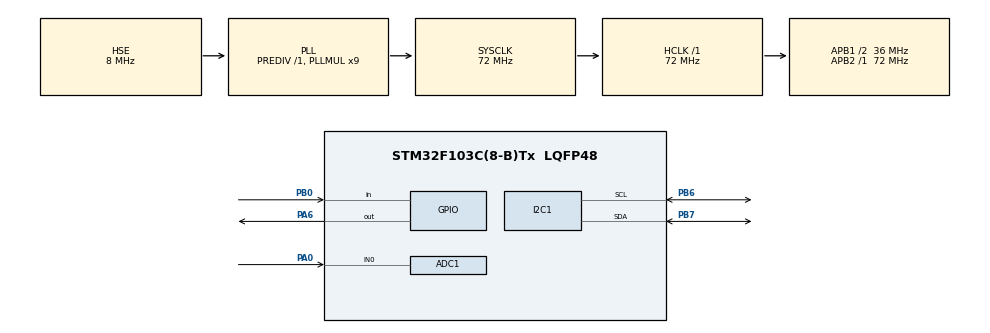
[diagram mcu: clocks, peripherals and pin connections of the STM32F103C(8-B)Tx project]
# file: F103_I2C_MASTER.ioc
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ADC1.Channel-0\#ChannelRegularConversion=ADC_CHANNEL_0
ADC1.ContinuousConvMode=ENABLE
ADC1.NbrOfConversionFlag=1
ADC1.Rank-0\#ChannelRegularConversion=1
ADC1.SamplingTime-0\#ChannelRegularConversion=ADC_SAMPLETIME_28CYCLES_5
ADC1.master=1
I2C1.AddressingMode=I2C_ADDRESSINGMODE_10BIT
I2C1.I2C_Mode=I2C_Fast
I2C1.OwnAddress=0x30F
Mcu.Family=STM32F1
Mcu.Name=STM32F103C(8-B)Tx
Mcu.Package=LQFP48
NVIC.ADC1_2_IRQn=true\:0\:0\:false\:false\:true\:true\:true
NVIC.I2C1_ER_IRQn=true\:0\:0\:false\:false\:true\:true\:true
NVIC.I2C1_EV_IRQn=true\:0\:0\:false\:false\:true\:true\:true
NVIC.PriorityGroup=NVIC_PRIORITYGROUP_4
PA0-WKUP.Signal=ADCx_IN0
PA13.Mode=Serial_Wire
PA13.Signal=SYS_JTMS-SWDIO
PA14.Mode=Serial_Wire
PA14.Signal=SYS_JTCK-SWCLK
PA6.GPIO_PuPd=GPIO_NOPULL
PA6.PinState=GPIO_PIN_SET
PA6.Signal=GPIO_Output
PB0.GPIO_PuPd=GPIO_PULLDOWN
PB0.Signal=GPIO_Input
PB6.GPIO_Mode=GPIO_MODE_AF_OD
PB6.GPIO_Speed=GPIO_SPEED_FREQ_HIGH
PB6.Mode=I2C
PB6.Signal=I2C1_SCL
PB7.GPIO_Speed=GPIO_SPEED_FREQ_HIGH
PB7.Mode=I2C
PB7.Signal=I2C1_SDA
PD0-OSC_IN.Mode=HSE-External-Oscillator
PD0-OSC_IN.Signal=RCC_OSC_IN
PD1-OSC_OUT.Mode=HSE-External-Oscillator
PD1-OSC_OUT.Signal=RCC_OSC_OUT
ProjectManager.HeapSize=0x200
ProjectManager.StackSize=0x400
ProjectManager.TargetToolchain=SW4STM32
RCC.ADCPresc=RCC_ADCPCLK2_DIV6
RCC.AHBFreq_Value=72000000
RCC.APB1CLKDivider=RCC_HCLK_DIV2
RCC.APB1Freq_Value=36000000
RCC.APB1TimFreq_Value=72000000
RCC.APB2Freq_Value=72000000
RCC.APB2TimFreq_Value=72000000
RCC.HCLKFreq_Value=72000000
RCC.PLLMUL=RCC_PLL_MUL9
RCC.PLLSourceVirtual=RCC_PLLSOURCE_HSE
RCC.SYSCLKFreq_VALUE=72000000
RCC.SYSCLKSource=RCC_SYSCLKSOURCE_PLLCLK
RCC.USBFreq_Value=72000000
SH.ADCx_IN0.0=ADC1_IN0,IN0
board=stm32f103-hal-i2c-two-boards-communication-slave

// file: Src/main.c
/* USER CODE BEGIN Header */
/**
  ******************************************************************************
  * @file           : main.c
  * @brief          : Main program body
  ******************************************************************************
  * @attention
  *
  * <h2><center>&copy; Copyright (c) 2019 STMicroelectronics.
  * All rights reserved.</center></h2>
  *
  * This software component is licensed by ST under BSD 3-Clause license,
  * the "License"; You may not use this file except in compliance with the
  * License. You may obtain a copy of the License at:
  *                        opensource.org/licenses/BSD-3-Clause
  *
  ******************************************************************************
  */
/* USER CODE END Header */

#include "main.h"

ADC_HandleTypeDef hadc1;

I2C_HandleTypeDef hi2c1;

/* USER CODE BEGIN PV */
uint8_t aTxBuffer[] = " ****I2C_TwoBoards communication based on Polling****";

/* Buffer used for reception */
uint8_t aRxBuffer[20];

/* USER CODE END PV */

void SystemClock_Config(void);
static void MX_GPIO_Init(void);
static void MX_I2C1_Init(void);
static void MX_ADC1_Init(void);
/* USER CODE BEGIN PFP */
static uint16_t Buffercmp(uint8_t* pBuffer1, uint8_t* pBuffer2, uint16_t BufferLength);
static void Error_Handler(void);
/* USER CODE END PFP */

int main(void)
{

  /* MCU Configuration--------------------------------------------------------*/

  /* Reset of all peripherals, Initializes the Flash interface and the Systick. */
  HAL_Init();

  /* Configure the system clock */
  SystemClock_Config();

  /* Initialize all configured peripherals */
  MX_GPIO_Init();
  MX_I2C1_Init();
  MX_ADC1_Init();
  /* USER CODE BEGIN 2 */
  /* The board sends the message and expects to receive it back */

    /*##-2- Start the transmission process #####################################*/
    /* While the I2C in reception process, user can transmit data through "aTxBuffer" buffer */
    /* Timeout is set to 10S */
    while(HAL_I2C_Master_Transmit(&hi2c1, (uint16_t)783, (uint8_t*)aTxBuffer, 20, 10000)!= HAL_OK)
    {
      /* Error_Handler() function is called when Timeout error occurs.
         When Acknowledge failure occurs (Slave don't acknowledge its address)
         Master restarts communication */
      if (HAL_I2C_GetError(&hi2c1) != HAL_I2C_ERROR_AF)
      {
        Error_Handler();
      }
    }

    /*##-3- Put I2C peripheral in reception process ############################*/
    /* Timeout is set to 10S */
    while(HAL_I2C_Master_Receive(&hi2c1, (uint16_t)783, (uint8_t *)aRxBuffer, 20, 10000) != HAL_OK)
    {
      /* Error_Handler() function is called when Timeout error occurs.
         When Acknowledge failure occurs (Slave don't acknowledge it's address)
         Master restarts communication */
      if (HAL_I2C_GetError(&hi2c1) != HAL_I2C_ERROR_AF)
      {
        Error_Handler();
      }
    }

    if(Buffercmp((uint8_t*)aTxBuffer,(uint8_t*)aRxBuffer,20))
    {
      /* Processing Error */
      Error_Handler();
    }
  /* USER CODE END 2 */

  /* Infinite loop */
  while (1)
  {

  }
}

static uint16_t Buffercmp(uint8_t* pBuffer1, uint8_t* pBuffer2, uint16_t BufferLength)
{
  while (BufferLength--)
  {
    if ((*pBuffer1) != *pBuffer2)
    {
      return BufferLength;
    }
    pBuffer1++;
    pBuffer2++;
  }

  return 0;
}

void SystemClock_Config(void)
{
  RCC_OscInitTypeDef RCC_OscInitStruct = {0};
  RCC_ClkInitTypeDef RCC_ClkInitStruct = {0};
  RCC_PeriphCLKInitTypeDef PeriphClkInit = {0};

  /** Initializes the CPU, AHB and APB busses clocks
  */
  RCC_OscInitStruct.OscillatorType = RCC_OSCILLATORTYPE_HSE;
  RCC_OscInitStruct.HSEState = RCC_HSE_ON;
  RCC_OscInitStruct.HSEPredivValue = RCC_HSE_PREDIV_DIV1;
  RCC_OscInitStruct.HSIState = RCC_HSI_ON;
  RCC_OscInitStruct.PLL.PLLState = RCC_PLL_ON;
  RCC_OscInitStruct.PLL.PLLSource = RCC_PLLSOURCE_HSE;
  RCC_OscInitStruct.PLL.PLLMUL = RCC_PLL_MUL9;
  if (HAL_RCC_OscConfig(&RCC_OscInitStruct) != HAL_OK)
  {
    Error_Handler();
  }
  /** Initializes the CPU, AHB and APB busses clocks
  */
  RCC_ClkInitStruct.ClockType = RCC_CLOCKTYPE_HCLK|RCC_CLOCKTYPE_SYSCLK
                              |RCC_CLOCKTYPE_PCLK1|RCC_CLOCKTYPE_PCLK2;
  RCC_ClkInitStruct.SYSCLKSource = RCC_SYSCLKSOURCE_PLLCLK;
  RCC_ClkInitStruct.AHBCLKDivider = RCC_SYSCLK_DIV1;
  RCC_ClkInitStruct.APB1CLKDivider = RCC_HCLK_DIV2;
  RCC_ClkInitStruct.APB2CLKDivider = RCC_HCLK_DIV1;

  if (HAL_RCC_ClockConfig(&RCC_ClkInitStruct, FLASH_LATENCY_2) != HAL_OK)
  {
    Error_Handler();
  }
  PeriphClkInit.PeriphClockSelection = RCC_PERIPHCLK_ADC;
  PeriphClkInit.AdcClockSelection = RCC_ADCPCLK2_DIV6;
  if (HAL_RCCEx_PeriphCLKConfig(&PeriphClkInit) != HAL_OK)
  {
    Error_Handler();
  }
}

static void MX_ADC1_Init(void)
{

  ADC_ChannelConfTypeDef sConfig = {0};

  /** Common config
  */
  hadc1.Instance = ADC1;
  hadc1.Init.ScanConvMode = ADC_SCAN_DISABLE;
  hadc1.Init.ContinuousConvMode = ENABLE;
  hadc1.Init.DiscontinuousConvMode = DISABLE;
  hadc1.Init.ExternalTrigConv = ADC_SOFTWARE_START;
  hadc1.Init.DataAlign = ADC_DATAALIGN_RIGHT;
  hadc1.Init.NbrOfConversion = 1;
  if (HAL_ADC_Init(&hadc1) != HAL_OK)
  {
    Error_Handler();
  }
  /** Configure Regular Channel
  */
  sConfig.Channel = ADC_CHANNEL_0;
  sConfig.Rank = ADC_REGULAR_RANK_1;
  sConfig.SamplingTime = ADC_SAMPLETIME_28CYCLES_5;
  if (HAL_ADC_ConfigChannel(&hadc1, &sConfig) != HAL_OK)
  {
    Error_Handler();
  }

}

static void MX_I2C1_Init(void)
{

  hi2c1.Instance = I2C1;
  hi2c1.Init.ClockSpeed = 400000;
  hi2c1.Init.DutyCycle = I2C_DUTYCYCLE_2;
  hi2c1.Init.OwnAddress1 = 783;
  hi2c1.Init.AddressingMode = I2C_ADDRESSINGMODE_10BIT;
  hi2c1.Init.DualAddressMode = I2C_DUALADDRESS_DISABLE;
  hi2c1.Init.OwnAddress2 = 0;
  hi2c1.Init.GeneralCallMode = I2C_GENERALCALL_DISABLE;
  hi2c1.Init.NoStretchMode = I2C_NOSTRETCH_DISABLE;
  if (HAL_I2C_Init(&hi2c1) != HAL_OK)
  {
    Error_Handler();
  }

}

static void MX_GPIO_Init(void)
{
  GPIO_InitTypeDef GPIO_InitStruct = {0};

  /* GPIO Ports Clock Enable */
  __HAL_RCC_GPIOC_CLK_ENABLE();
  __HAL_RCC_GPIOD_CLK_ENABLE();
  __HAL_RCC_GPIOA_CLK_ENABLE();
  __HAL_RCC_GPIOB_CLK_ENABLE();

  /*Configure GPIO pin Output Level */
  HAL_GPIO_WritePin(GPIOA, GPIO_PIN_6, GPIO_PIN_SET);

  /*Configure GPIO pins : PC13 PC14 PC15 */
  GPIO_InitStruct.Pin = GPIO_PIN_13|GPIO_PIN_14|GPIO_PIN_15;
  GPIO_InitStruct.Mode = GPIO_MODE_ANALOG;
  HAL_GPIO_Init(GPIOC, &GPIO_InitStruct);

  /*Configure GPIO pins : PA1 PA2 PA3 PA4
                           PA5 PA7 PA8 PA9
                           PA10 PA11 PA12 PA15 */
  GPIO_InitStruct.Pin = GPIO_PIN_1|GPIO_PIN_2|GPIO_PIN_3|GPIO_PIN_4
                          |GPIO_PIN_5|GPIO_PIN_7|GPIO_PIN_8|GPIO_PIN_9
                          |GPIO_PIN_10|GPIO_PIN_11|GPIO_PIN_12|GPIO_PIN_15;
  GPIO_InitStruct.Mode = GPIO_MODE_ANALOG;
  HAL_GPIO_Init(GPIOA, &GPIO_InitStruct);

  /*Configure GPIO pin : PA6 */
  GPIO_InitStruct.Pin = GPIO_PIN_6;
  GPIO_InitStruct.Mode = GPIO_MODE_OUTPUT_PP;
  GPIO_InitStruct.Pull = GPIO_NOPULL;
  GPIO_InitStruct.Speed = GPIO_SPEED_FREQ_LOW;
  HAL_GPIO_Init(GPIOA, &GPIO_InitStruct);

  /*Configure GPIO pin : PB0 */
  GPIO_InitStruct.Pin = GPIO_PIN_0;
  GPIO_InitStruct.Mode = GPIO_MODE_INPUT;
  GPIO_InitStruct.Pull = GPIO_PULLDOWN;
  HAL_GPIO_Init(GPIOB, &GPIO_InitStruct);

  /*Configure GPIO pins : PB1 PB2 PB10 PB11
                           PB12 PB13 PB14 PB15
                           PB3 PB4 PB5 PB8
                           PB9 */
  GPIO_InitStruct.Pin = GPIO_PIN_1|GPIO_PIN_2|GPIO_PIN_10|GPIO_PIN_11
                          |GPIO_PIN_12|GPIO_PIN_13|GPIO_PIN_14|GPIO_PIN_15
                          |GPIO_PIN_3|GPIO_PIN_4|GPIO_PIN_5|GPIO_PIN_8
                          |GPIO_PIN_9;
  GPIO_InitStruct.Mode = GPIO_MODE_ANALOG;
  HAL_GPIO_Init(GPIOB, &GPIO_InitStruct);

}

void Error_Handler(void)
{
}

/************************ (C) COPYRIGHT STMicroelectronics *****END OF FILE****/
